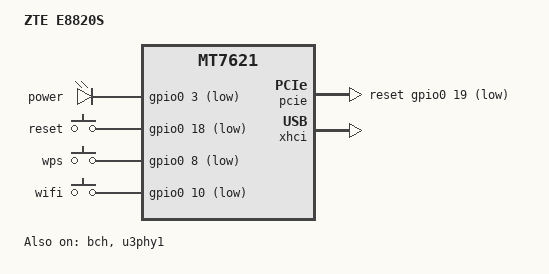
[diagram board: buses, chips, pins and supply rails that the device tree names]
/dts-v1/;

#include "mt7621.dtsi"
#include <dt-bindings/input/input.h>
#include "mt7621-spi-16m-layout.dtsi"
#include "mt7621-raeth-gmac2.dtsi"
#include "mt7621-pinctrl-default-gpio.dtsi"

/ {
	compatible = "mediatek,mt7621-soc";
	model = "ZTE E8820S";

	chosen {
		bootargs = "console=ttyS0,115200";
	};

	leds {
		compatible = "gpio-leds";
    
    		sys_white {
			label = "power";
			gpios = <&gpio0 3 GPIO_ACTIVE_LOW>;
		};
	};
	
	gpio-keys-polled {
		compatible = "gpio-keys-polled";
		#address-cells = <1>;
		#size-cells = <0>;
		poll-interval = <20>;

		reset {
			label = "reset";
			gpios = <&gpio0 18 GPIO_ACTIVE_LOW>;
			linux,code = <KEY_RESTART>;
		};
		
		wps {
			label = "wps";
			gpios = <&gpio0 8 GPIO_ACTIVE_LOW>;
			linux,code = <KEY_WPS_BUTTON>;
		};
		
		wifi {
			label = "wifi";
			gpios = <&gpio0 10 GPIO_ACTIVE_LOW>;
			linux,code = <KEY_RFKILL>;
		};
	};
	
};

&bch {
	status = "okay";
};

&pcie {
	status = "okay";
	reset-gpios = <&gpio0 19 1>, <&gpio0 4 1>;
	reset-gpio-names = "pcie0", "pcie1";

};

&xhci {
	status = "okay";
};

&u3phy1 {
	status = "okay";
};
